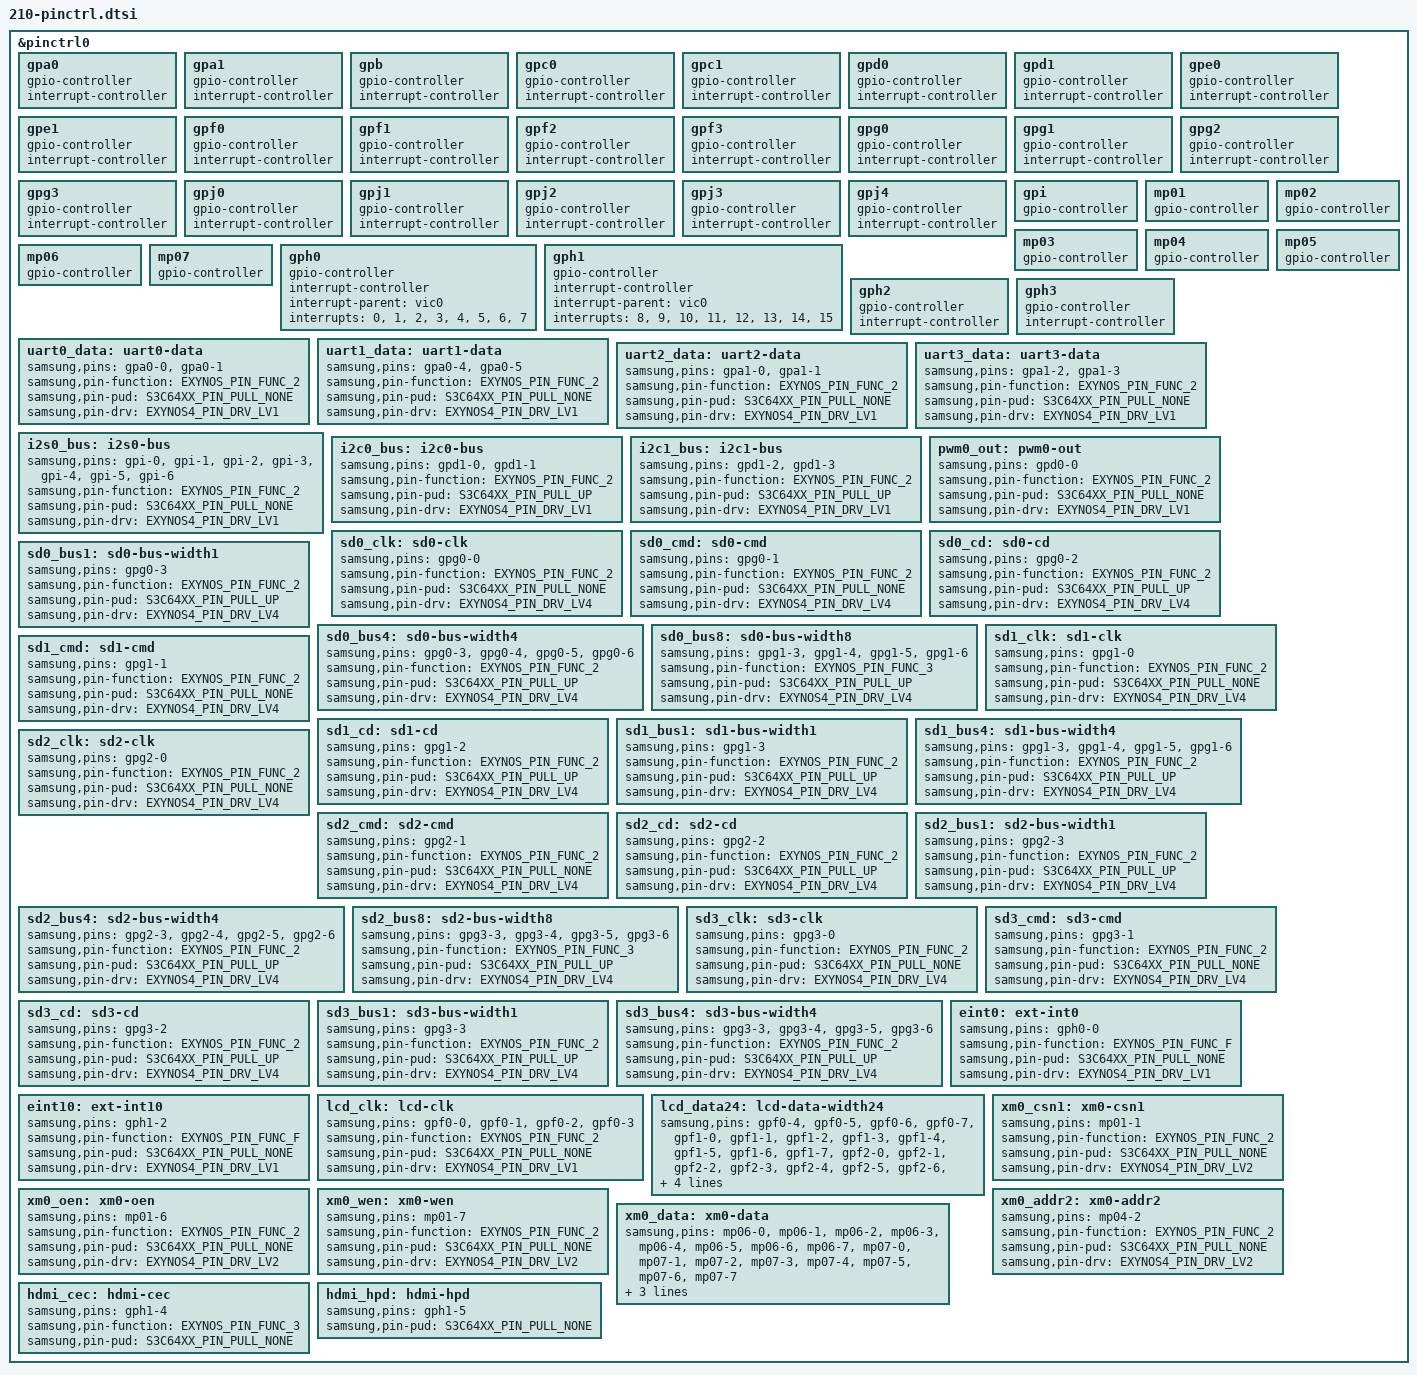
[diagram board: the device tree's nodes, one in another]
// SPDX-License-Identifier: GPL-2.0
/*
 * Samsung's S5PV210 SoC device tree source
 *
 * Copyright (c) 2013-2014 Samsung Electronics, Co. Ltd.
 *
 * Mateusz Krawczuk <m.krawczuk@partner.samsung.com>
 * Tomasz Figa <t.figa@samsung.com>
 *
 * Samsung's S5PV210 SoC device nodes are listed in this file. S5PV210
 * based board files can include this file and provide values for board specfic
 * bindings.
 *
 * Note: This file does not include device nodes for all the controllers in
 * S5PV210 SoC. As device tree coverage for S5PV210 increases, additional
 * nodes can be added to this file.
 */

#include <dt-bindings/pinctrl/samsung.h>

#define PIN_SLP(_pin, _mode, _pull)					\
	_pin {								\
		samsung,pins = #_pin;					\
		samsung,pin-con-pdn = <EXYNOS_PIN_PDN_ ##_mode>;	\
		samsung,pin-pud-pdn = <S3C64XX_PIN_PULL_ ##_pull>;	\
	}

&pinctrl0 {
	gpa0: gpa0 {
		gpio-controller;
		#gpio-cells = <2>;

		interrupt-controller;
		#interrupt-cells = <2>;
	};

	gpa1: gpa1 {
		gpio-controller;
		#gpio-cells = <2>;

		interrupt-controller;
		#interrupt-cells = <2>;
	};

	gpb: gpb {
		gpio-controller;
		#gpio-cells = <2>;

		interrupt-controller;
		#interrupt-cells = <2>;
	};

	gpc0: gpc0 {
		gpio-controller;
		#gpio-cells = <2>;

		interrupt-controller;
		#interrupt-cells = <2>;
	};

	gpc1: gpc1 {
		gpio-controller;
		#gpio-cells = <2>;

		interrupt-controller;
		#interrupt-cells = <2>;
	};

	gpd0: gpd0 {
		gpio-controller;
		#gpio-cells = <2>;

		interrupt-controller;
		#interrupt-cells = <2>;
	};

	gpd1: gpd1 {
		gpio-controller;
		#gpio-cells = <2>;

		interrupt-controller;
		#interrupt-cells = <2>;
	};

	gpe0: gpe0 {
		gpio-controller;
		#gpio-cells = <2>;

		interrupt-controller;
		#interrupt-cells = <2>;
	};

	gpe1: gpe1 {
		gpio-controller;
		#gpio-cells = <2>;

		interrupt-controller;
		#interrupt-cells = <2>;
	};

	gpf0: gpf0 {
		gpio-controller;
		#gpio-cells = <2>;

		interrupt-controller;
		#interrupt-cells = <2>;
	};

	gpf1: gpf1 {
		gpio-controller;
		#gpio-cells = <2>;

		interrupt-controller;
		#interrupt-cells = <2>;
	};

	gpf2: gpf2 {
		gpio-controller;
		#gpio-cells = <2>;

		interrupt-controller;
		#interrupt-cells = <2>;
	};

	gpf3: gpf3 {
		gpio-controller;
		#gpio-cells = <2>;

		interrupt-controller;
		#interrupt-cells = <2>;
	};

	gpg0: gpg0 {
		gpio-controller;
		#gpio-cells = <2>;

		interrupt-controller;
		#interrupt-cells = <2>;
	};

	gpg1: gpg1 {
		gpio-controller;
		#gpio-cells = <2>;

		interrupt-controller;
		#interrupt-cells = <2>;
	};

	gpg2: gpg2 {
		gpio-controller;
		#gpio-cells = <2>;

		interrupt-controller;
		#interrupt-cells = <2>;
	};

	gpg3: gpg3 {
		gpio-controller;
		#gpio-cells = <2>;

		interrupt-controller;
		#interrupt-cells = <2>;
	};

	gpj0: gpj0 {
		gpio-controller;
		#gpio-cells = <2>;

		interrupt-controller;
		#interrupt-cells = <2>;
	};

	gpj1: gpj1 {
		gpio-controller;
		#gpio-cells = <2>;

		interrupt-controller;
		#interrupt-cells = <2>;
	};

	gpj2: gpj2 {
		gpio-controller;
		#gpio-cells = <2>;

		interrupt-controller;
		#interrupt-cells = <2>;
	};

	gpj3: gpj3 {
		gpio-controller;
		#gpio-cells = <2>;

		interrupt-controller;
		#interrupt-cells = <2>;
	};

	gpj4: gpj4 {
		gpio-controller;
		#gpio-cells = <2>;

		interrupt-controller;
		#interrupt-cells = <2>;
	};

	gpi: gpi {
		gpio-controller;
		#gpio-cells = <2>;
	};

	mp01: mp01 {
		gpio-controller;
		#gpio-cells = <2>;
	};

	mp02: mp02 {
		gpio-controller;
		#gpio-cells = <2>;
	};

	mp03: mp03 {
		gpio-controller;
		#gpio-cells = <2>;
	};

	mp04: mp04 {
		gpio-controller;
		#gpio-cells = <2>;
	};

	mp05: mp05 {
		gpio-controller;
		#gpio-cells = <2>;
	};

	mp06: mp06 {
		gpio-controller;
		#gpio-cells = <2>;
	};

	mp07: mp07 {
		gpio-controller;
		#gpio-cells = <2>;
	};

	gph0: gph0 {
		gpio-controller;
		interrupt-controller;
		interrupt-parent = <&vic0>;
		interrupts = <0>, <1>, <2>, <3>,
				<4>, <5>, <6>, <7>;
		#gpio-cells = <2>;
		#interrupt-cells = <2>;
	};

	gph1: gph1 {
		gpio-controller;
		interrupt-controller;
		interrupt-parent = <&vic0>;
		interrupts = <8>, <9>, <10>, <11>,
				<12>, <13>, <14>, <15>;
		#gpio-cells = <2>;
		#interrupt-cells = <2>;
	};

	gph2: gph2 {
		gpio-controller;
		#gpio-cells = <2>;

		interrupt-controller;
		#interrupt-cells = <2>;
	};

	gph3: gph3 {
		gpio-controller;
		#gpio-cells = <2>;

		interrupt-controller;
		#interrupt-cells = <2>;
	};

	uart0_data: uart0-data {
		samsung,pins = "gpa0-0", "gpa0-1";
		samsung,pin-function = <EXYNOS_PIN_FUNC_2>;
		samsung,pin-pud = <S3C64XX_PIN_PULL_NONE>;
		samsung,pin-drv = <EXYNOS4_PIN_DRV_LV1>;
	};

	uart1_data: uart1-data {
		samsung,pins = "gpa0-4", "gpa0-5";
		samsung,pin-function = <EXYNOS_PIN_FUNC_2>;
		samsung,pin-pud = <S3C64XX_PIN_PULL_NONE>;
		samsung,pin-drv = <EXYNOS4_PIN_DRV_LV1>;
	};

	uart2_data: uart2-data {
		samsung,pins = "gpa1-0", "gpa1-1";
		samsung,pin-function = <EXYNOS_PIN_FUNC_2>;
		samsung,pin-pud = <S3C64XX_PIN_PULL_NONE>;
		samsung,pin-drv = <EXYNOS4_PIN_DRV_LV1>;
	};

	uart3_data: uart3-data {
		samsung,pins = "gpa1-2", "gpa1-3";
		samsung,pin-function = <EXYNOS_PIN_FUNC_2>;
		samsung,pin-pud = <S3C64XX_PIN_PULL_NONE>;
		samsung,pin-drv = <EXYNOS4_PIN_DRV_LV1>;
	};

	i2s0_bus: i2s0-bus {
		samsung,pins = "gpi-0", "gpi-1", "gpi-2", "gpi-3",
				"gpi-4", "gpi-5", "gpi-6";
		samsung,pin-function = <EXYNOS_PIN_FUNC_2>;
		samsung,pin-pud = <S3C64XX_PIN_PULL_NONE>;
		samsung,pin-drv = <EXYNOS4_PIN_DRV_LV1>;
	};

	i2c0_bus: i2c0-bus {
		samsung,pins = "gpd1-0", "gpd1-1";
		samsung,pin-function = <EXYNOS_PIN_FUNC_2>;
		samsung,pin-pud = <S3C64XX_PIN_PULL_UP>;
		samsung,pin-drv = <EXYNOS4_PIN_DRV_LV1>;
	};

	i2c1_bus: i2c1-bus {
		samsung,pins = "gpd1-2", "gpd1-3";
		samsung,pin-function = <EXYNOS_PIN_FUNC_2>;
		samsung,pin-pud = <S3C64XX_PIN_PULL_UP>;
		samsung,pin-drv = <EXYNOS4_PIN_DRV_LV1>;
	};

	pwm0_out: pwm0-out {
		samsung,pins = "gpd0-0";
		samsung,pin-function = <EXYNOS_PIN_FUNC_2>;
		samsung,pin-pud = <S3C64XX_PIN_PULL_NONE>;
		samsung,pin-drv = <EXYNOS4_PIN_DRV_LV1>;
	};

	sd0_clk: sd0-clk {
		samsung,pins = "gpg0-0";
		samsung,pin-function = <EXYNOS_PIN_FUNC_2>;
		samsung,pin-pud = <S3C64XX_PIN_PULL_NONE>;
		samsung,pin-drv = <EXYNOS4_PIN_DRV_LV4>;
	};

	sd0_cmd: sd0-cmd {
		samsung,pins = "gpg0-1";
		samsung,pin-function = <EXYNOS_PIN_FUNC_2>;
		samsung,pin-pud = <S3C64XX_PIN_PULL_NONE>;
		samsung,pin-drv = <EXYNOS4_PIN_DRV_LV4>;
	};

	sd0_cd: sd0-cd {
		samsung,pins = "gpg0-2";
		samsung,pin-function = <EXYNOS_PIN_FUNC_2>;
		samsung,pin-pud = <S3C64XX_PIN_PULL_UP>;
		samsung,pin-drv = <EXYNOS4_PIN_DRV_LV4>;
	};

	sd0_bus1: sd0-bus-width1 {
		samsung,pins = "gpg0-3";
		samsung,pin-function = <EXYNOS_PIN_FUNC_2>;
		samsung,pin-pud = <S3C64XX_PIN_PULL_UP>;
		samsung,pin-drv = <EXYNOS4_PIN_DRV_LV4>;
	};

	sd0_bus4: sd0-bus-width4 {
		samsung,pins = "gpg0-3", "gpg0-4", "gpg0-5", "gpg0-6";
		samsung,pin-function = <EXYNOS_PIN_FUNC_2>;
		samsung,pin-pud = <S3C64XX_PIN_PULL_UP>;
		samsung,pin-drv = <EXYNOS4_PIN_DRV_LV4>;
	};

	sd0_bus8: sd0-bus-width8 {
		samsung,pins = "gpg1-3", "gpg1-4", "gpg1-5", "gpg1-6";
		samsung,pin-function = <EXYNOS_PIN_FUNC_3>;
		samsung,pin-pud = <S3C64XX_PIN_PULL_UP>;
		samsung,pin-drv = <EXYNOS4_PIN_DRV_LV4>;
	};

	sd1_clk: sd1-clk {
		samsung,pins = "gpg1-0";
		samsung,pin-function = <EXYNOS_PIN_FUNC_2>;
		samsung,pin-pud = <S3C64XX_PIN_PULL_NONE>;
		samsung,pin-drv = <EXYNOS4_PIN_DRV_LV4>;
	};

	sd1_cmd: sd1-cmd {
		samsung,pins = "gpg1-1";
		samsung,pin-function = <EXYNOS_PIN_FUNC_2>;
		samsung,pin-pud = <S3C64XX_PIN_PULL_NONE>;
		samsung,pin-drv = <EXYNOS4_PIN_DRV_LV4>;
	};

	sd1_cd: sd1-cd {
		samsung,pins = "gpg1-2";
		samsung,pin-function = <EXYNOS_PIN_FUNC_2>;
		samsung,pin-pud = <S3C64XX_PIN_PULL_UP>;
		samsung,pin-drv = <EXYNOS4_PIN_DRV_LV4>;
	};

	sd1_bus1: sd1-bus-width1 {
		samsung,pins = "gpg1-3";
		samsung,pin-function = <EXYNOS_PIN_FUNC_2>;
		samsung,pin-pud = <S3C64XX_PIN_PULL_UP>;
		samsung,pin-drv = <EXYNOS4_PIN_DRV_LV4>;
	};

	sd1_bus4: sd1-bus-width4 {
		samsung,pins = "gpg1-3", "gpg1-4", "gpg1-5", "gpg1-6";
		samsung,pin-function = <EXYNOS_PIN_FUNC_2>;
		samsung,pin-pud = <S3C64XX_PIN_PULL_UP>;
		samsung,pin-drv = <EXYNOS4_PIN_DRV_LV4>;
	};

	sd2_clk: sd2-clk {
		samsung,pins = "gpg2-0";
		samsung,pin-function = <EXYNOS_PIN_FUNC_2>;
		samsung,pin-pud = <S3C64XX_PIN_PULL_NONE>;
		samsung,pin-drv = <EXYNOS4_PIN_DRV_LV4>;
	};

	sd2_cmd: sd2-cmd {
		samsung,pins = "gpg2-1";
		samsung,pin-function = <EXYNOS_PIN_FUNC_2>;
		samsung,pin-pud = <S3C64XX_PIN_PULL_NONE>;
		samsung,pin-drv = <EXYNOS4_PIN_DRV_LV4>;
	};

	sd2_cd: sd2-cd {
		samsung,pins = "gpg2-2";
		samsung,pin-function = <EXYNOS_PIN_FUNC_2>;
		samsung,pin-pud = <S3C64XX_PIN_PULL_UP>;
		samsung,pin-drv = <EXYNOS4_PIN_DRV_LV4>;
	};

	sd2_bus1: sd2-bus-width1 {
		samsung,pins = "gpg2-3";
		samsung,pin-function = <EXYNOS_PIN_FUNC_2>;
		samsung,pin-pud = <S3C64XX_PIN_PULL_UP>;
		samsung,pin-drv = <EXYNOS4_PIN_DRV_LV4>;
	};

	sd2_bus4: sd2-bus-width4 {
		samsung,pins = "gpg2-3", "gpg2-4", "gpg2-5", "gpg2-6";
		samsung,pin-function = <EXYNOS_PIN_FUNC_2>;
		samsung,pin-pud = <S3C64XX_PIN_PULL_UP>;
		samsung,pin-drv = <EXYNOS4_PIN_DRV_LV4>;
	};

	sd2_bus8: sd2-bus-width8 {
		samsung,pins = "gpg3-3", "gpg3-4", "gpg3-5", "gpg3-6";
		samsung,pin-function = <EXYNOS_PIN_FUNC_3>;
		samsung,pin-pud = <S3C64XX_PIN_PULL_UP>;
		samsung,pin-drv = <EXYNOS4_PIN_DRV_LV4>;
	};

	sd3_clk: sd3-clk {
		samsung,pins = "gpg3-0";
		samsung,pin-function = <EXYNOS_PIN_FUNC_2>;
		samsung,pin-pud = <S3C64XX_PIN_PULL_NONE>;
		samsung,pin-drv = <EXYNOS4_PIN_DRV_LV4>;
	};

	sd3_cmd: sd3-cmd {
		samsung,pins = "gpg3-1";
		samsung,pin-function = <EXYNOS_PIN_FUNC_2>;
		samsung,pin-pud = <S3C64XX_PIN_PULL_NONE>;
		samsung,pin-drv = <EXYNOS4_PIN_DRV_LV4>;
	};

	sd3_cd: sd3-cd {
		samsung,pins = "gpg3-2";
		samsung,pin-function = <EXYNOS_PIN_FUNC_2>;
		samsung,pin-pud = <S3C64XX_PIN_PULL_UP>;
		samsung,pin-drv = <EXYNOS4_PIN_DRV_LV4>;
	};

	sd3_bus1: sd3-bus-width1 {
		samsung,pins = "gpg3-3";
		samsung,pin-function = <EXYNOS_PIN_FUNC_2>;
		samsung,pin-pud = <S3C64XX_PIN_PULL_UP>;
		samsung,pin-drv = <EXYNOS4_PIN_DRV_LV4>;
	};

	sd3_bus4: sd3-bus-width4 {
		samsung,pins = "gpg3-3", "gpg3-4", "gpg3-5", "gpg3-6";
		samsung,pin-function = <EXYNOS_PIN_FUNC_2>;
		samsung,pin-pud = <S3C64XX_PIN_PULL_UP>;
		samsung,pin-drv = <EXYNOS4_PIN_DRV_LV4>;
	};

	eint0: ext-int0 {
		samsung,pins = "gph0-0";
		samsung,pin-function = <EXYNOS_PIN_FUNC_F>;
		samsung,pin-pud = <S3C64XX_PIN_PULL_NONE>;
		samsung,pin-drv = <EXYNOS4_PIN_DRV_LV1>;
	};

	eint10: ext-int10 {
		samsung,pins = "gph1-2";
		samsung,pin-function = <EXYNOS_PIN_FUNC_F>;
		samsung,pin-pud = <S3C64XX_PIN_PULL_NONE>;
		samsung,pin-drv = <EXYNOS4_PIN_DRV_LV1>;
	};

	lcd_clk: lcd-clk {
		samsung,pins = "gpf0-0", "gpf0-1", "gpf0-2", "gpf0-3";
		samsung,pin-function = <EXYNOS_PIN_FUNC_2>;
		samsung,pin-pud = <S3C64XX_PIN_PULL_NONE>;
		samsung,pin-drv = <EXYNOS4_PIN_DRV_LV1>;
	};

	lcd_data24: lcd-data-width24 {
		samsung,pins =  "gpf0-4", "gpf0-5", "gpf0-6", "gpf0-7",
				"gpf1-0", "gpf1-1", "gpf1-2", "gpf1-3",
				"gpf1-4", "gpf1-5", "gpf1-6", "gpf1-7",
				"gpf2-0", "gpf2-1", "gpf2-2", "gpf2-3",
				"gpf2-4", "gpf2-5", "gpf2-6", "gpf2-7",
				"gpf3-0", "gpf3-1", "gpf3-2", "gpf3-3";
		samsung,pin-function = <EXYNOS_PIN_FUNC_2>;
		samsung,pin-pud = <S3C64XX_PIN_PULL_NONE>;
		samsung,pin-drv = <EXYNOS4_PIN_DRV_LV1>;
	};

	xm0_csn1: xm0-csn1 {
		samsung,pins = "mp01-1";
		samsung,pin-function = <EXYNOS_PIN_FUNC_2>;
		samsung,pin-pud = <S3C64XX_PIN_PULL_NONE>;
		samsung,pin-drv = <EXYNOS4_PIN_DRV_LV2>;
	};

	xm0_oen: xm0-oen {
		samsung,pins = "mp01-6";
		samsung,pin-function = <EXYNOS_PIN_FUNC_2>;
		samsung,pin-pud = <S3C64XX_PIN_PULL_NONE>;
		samsung,pin-drv = <EXYNOS4_PIN_DRV_LV2>;
	};

	xm0_wen: xm0-wen {
		samsung,pins = "mp01-7";
		samsung,pin-function = <EXYNOS_PIN_FUNC_2>;
		samsung,pin-pud = <S3C64XX_PIN_PULL_NONE>;
		samsung,pin-drv = <EXYNOS4_PIN_DRV_LV2>;
	};

	xm0_addr2: xm0-addr2 {
		samsung,pins = "mp04-2";
		samsung,pin-function = <EXYNOS_PIN_FUNC_2>;
		samsung,pin-pud = <S3C64XX_PIN_PULL_NONE>;
		samsung,pin-drv = <EXYNOS4_PIN_DRV_LV2>;
	};

	xm0_data: xm0-data {
		samsung,pins = "mp06-0", "mp06-1", "mp06-2", "mp06-3",
				"mp06-4", "mp06-5", "mp06-6", "mp06-7",
				"mp07-0", "mp07-1", "mp07-2", "mp07-3",
				"mp07-4", "mp07-5", "mp07-6", "mp07-7";
		samsung,pin-function = <EXYNOS_PIN_FUNC_2>;
		samsung,pin-pud = <S3C64XX_PIN_PULL_NONE>;
		samsung,pin-drv = <EXYNOS4_PIN_DRV_LV2>;
	};

	hdmi_cec: hdmi-cec {
		samsung,pins = "gph1-4";
		samsung,pin-function = <EXYNOS_PIN_FUNC_3>;
		samsung,pin-pud = <S3C64XX_PIN_PULL_NONE>;
	};

	hdmi_hpd: hdmi-hpd {
		samsung,pins = "gph1-5";
		samsung,pin-pud = <S3C64XX_PIN_PULL_NONE>;
	};
};
